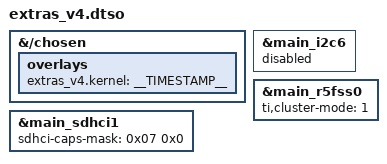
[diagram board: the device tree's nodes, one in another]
/dts-v1/;
/plugin/;

&{/chosen} {
	overlays {
		extras_v4.kernel = __TIMESTAMP__;
	};
};

&main_sdhci1 {
    sdhci-caps-mask = <0x07 0x0>;
};

&main_i2c6 {
	status = "disabled";
};

&main_r5fss0 {
    ti,cluster-mode = <1>;
};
